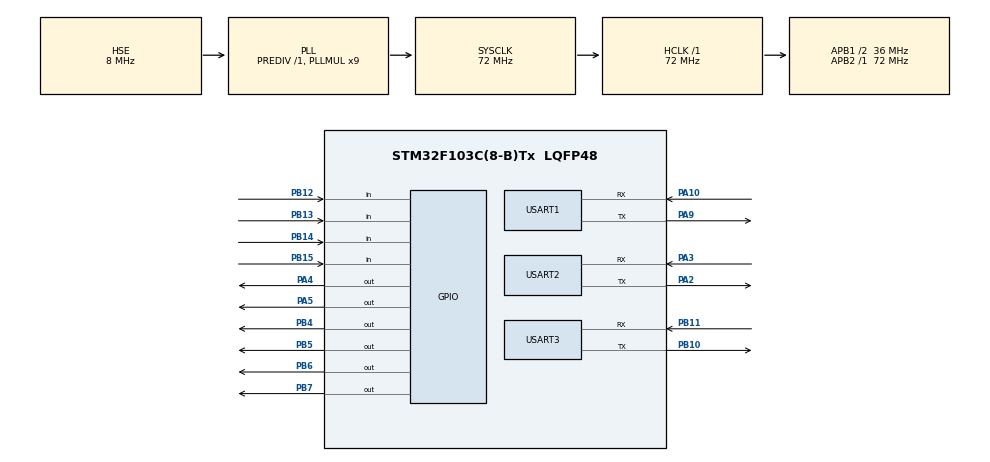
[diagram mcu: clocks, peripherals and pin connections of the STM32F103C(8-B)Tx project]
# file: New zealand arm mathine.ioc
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FREERTOS.INCLUDE_eTaskGetState=1
FREERTOS.Queues01=serialRecQueue,16,uint16_t,0,Dynamic,NULL,NULL;serialSendQueue,16,uint16_t,0,Dynamic,NULL,NULL
FREERTOS.Tasks01=defaultTask,0,128,StartDefaultTask,Default,NULL,Dynamic,NULL,NULL;ledTask,-2,128,LedTask,Default,NULL,Dynamic,NULL,NULL
FREERTOS.configGENERATE_RUN_TIME_STATS=1
Mcu.Family=STM32F1
Mcu.Name=STM32F103C(8-B)Tx
Mcu.Package=LQFP48
NVIC.PriorityGroup=NVIC_PRIORITYGROUP_4
NVIC.TIM1_UP_IRQn=true\:0\:0\:false\:false\:true\:false\:false\:true
NVIC.TimeBase=TIM1_UP_IRQn
NVIC.TimeBaseIP=TIM1
NVIC.USART1_IRQn=true\:5\:0\:false\:false\:true\:true\:true\:true
NVIC.USART2_IRQn=true\:5\:0\:false\:false\:true\:true\:true\:true
NVIC.USART3_IRQn=true\:5\:0\:false\:false\:true\:true\:true\:true
PA10.Mode=Asynchronous
PA10.Signal=USART1_RX
PA13.Mode=Serial_Wire
PA13.Signal=SYS_JTMS-SWDIO
PA14.Mode=Serial_Wire
PA14.Signal=SYS_JTCK-SWCLK
PA2.Mode=Asynchronous
PA2.Signal=USART2_TX
PA3.Mode=Asynchronous
PA3.Signal=USART2_RX
PA4.Signal=GPIO_Output
PA5.Signal=GPIO_Output
PA9.Mode=Asynchronous
PA9.Signal=USART1_TX
PB10.Mode=Asynchronous
PB10.Signal=USART3_TX
PB11.Mode=Asynchronous
PB11.Signal=USART3_RX
PB12.Signal=GPIO_Input
PB13.Signal=GPIO_Input
PB14.Signal=GPIO_Input
PB15.Signal=GPIO_Input
PB4.Signal=GPIO_Output
PB5.Signal=GPIO_Output
PB6.Signal=GPIO_Output
PB7.Signal=GPIO_Output
PC14-OSC32_IN.Mode=LSE-External-Oscillator
PC14-OSC32_IN.Signal=RCC_OSC32_IN
PC15-OSC32_OUT.Mode=LSE-External-Oscillator
PC15-OSC32_OUT.Signal=RCC_OSC32_OUT
PD0-OSC_IN.Mode=HSE-External-Oscillator
PD0-OSC_IN.Signal=RCC_OSC_IN
PD1-OSC_OUT.Mode=HSE-External-Oscillator
PD1-OSC_OUT.Signal=RCC_OSC_OUT
ProjectManager.HeapSize=0x200
ProjectManager.StackSize=0x400
ProjectManager.TargetToolchain=MDK-ARM V5
RCC.AHBFreq_Value=72000000
RCC.APB1CLKDivider=RCC_HCLK_DIV2
RCC.APB1Freq_Value=36000000
RCC.APB1TimFreq_Value=72000000
RCC.APB2Freq_Value=72000000
RCC.APB2TimFreq_Value=72000000
RCC.HCLKFreq_Value=72000000
RCC.PLLMUL=RCC_PLL_MUL9
RCC.PLLSourceVirtual=RCC_PLLSOURCE_HSE
RCC.SYSCLKFreq_VALUE=72000000
RCC.SYSCLKSource=RCC_SYSCLKSOURCE_PLLCLK
RCC.USBFreq_Value=72000000
USART1.VirtualMode=VM_ASYNC
USART2.VirtualMode=VM_ASYNC
USART3.VirtualMode=VM_ASYNC
VP_FREERTOS_VS_CMSIS_V1.Mode=CMSIS_V1
VP_IWDG_VS_IWDG.Mode=IWDG_Activate
VP_SYS_VS_tim1.Mode=TIM1
board=custom

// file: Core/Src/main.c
/* USER CODE BEGIN Header */
/**
  ******************************************************************************
  * @file           : main.c
  * @brief          : Main program body
  ******************************************************************************
  * @attention
  *
  * <h2><center>&copy; Copyright (c) 2019 STMicroelectronics.
  * All rights reserved.</center></h2>
  *
  * This software component is licensed by ST under Ultimate Liberty license
  * SLA0044, the "License"; You may not use this file except in compliance with
  * the License. You may obtain a copy of the License at:
  *                             www.st.com/SLA0044
  *
  ******************************************************************************
  */
/* USER CODE END Header */

#include "main.h"
#include "cmsis_os.h"
#include "iwdg.h"
#include "usart.h"
#include "gpio.h"

void SystemClock_Config(void);
void MX_FREERTOS_Init(void);

int main(void)
{

  /* MCU Configuration--------------------------------------------------------*/

  /* Reset of all peripherals, Initializes the Flash interface and the Systick. */
  HAL_Init();

  /* Configure the system clock */
  SystemClock_Config();

  /* Initialize all configured peripherals */
  MX_GPIO_Init();
  MX_IWDG_Init();
  MX_USART1_UART_Init();
  MX_USART2_UART_Init();
  MX_USART3_UART_Init();

  /* Call init function for freertos objects (in freertos.c) */
  MX_FREERTOS_Init();

  /* Start scheduler */
  osKernelStart();
//	vTaskStartScheduler();

  /* We should never get here as control is now taken by the scheduler */

  /* Infinite loop */
  while (1)
  {

  }
}

void SystemClock_Config(void)
{
  RCC_OscInitTypeDef RCC_OscInitStruct = {0};
  RCC_ClkInitTypeDef RCC_ClkInitStruct = {0};

  /** Initializes the CPU, AHB and APB busses clocks
  */
  RCC_OscInitStruct.OscillatorType = RCC_OSCILLATORTYPE_LSI|RCC_OSCILLATORTYPE_HSE;
  RCC_OscInitStruct.HSEState = RCC_HSE_ON;
  RCC_OscInitStruct.HSEPredivValue = RCC_HSE_PREDIV_DIV1;
  RCC_OscInitStruct.HSIState = RCC_HSI_ON;
  RCC_OscInitStruct.LSIState = RCC_LSI_ON;
  RCC_OscInitStruct.PLL.PLLState = RCC_PLL_ON;
  RCC_OscInitStruct.PLL.PLLSource = RCC_PLLSOURCE_HSE;
  RCC_OscInitStruct.PLL.PLLMUL = RCC_PLL_MUL9;
  if (HAL_RCC_OscConfig(&RCC_OscInitStruct) != HAL_OK)
  {
    Error_Handler();
  }
  /** Initializes the CPU, AHB and APB busses clocks
  */
  RCC_ClkInitStruct.ClockType = RCC_CLOCKTYPE_HCLK|RCC_CLOCKTYPE_SYSCLK
                              |RCC_CLOCKTYPE_PCLK1|RCC_CLOCKTYPE_PCLK2;
  RCC_ClkInitStruct.SYSCLKSource = RCC_SYSCLKSOURCE_PLLCLK;
  RCC_ClkInitStruct.AHBCLKDivider = RCC_SYSCLK_DIV1;
  RCC_ClkInitStruct.APB1CLKDivider = RCC_HCLK_DIV2;
  RCC_ClkInitStruct.APB2CLKDivider = RCC_HCLK_DIV1;

  if (HAL_RCC_ClockConfig(&RCC_ClkInitStruct, FLASH_LATENCY_2) != HAL_OK)
  {
    Error_Handler();
  }
}

void HAL_TIM_PeriodElapsedCallback(TIM_HandleTypeDef *htim)
{
  if (htim->Instance == TIM1) {
    HAL_IncTick();
  }
}

void Error_Handler(void)
{
}

/************************ (C) COPYRIGHT STMicroelectronics *****END OF FILE****/

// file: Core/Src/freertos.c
/* USER CODE BEGIN Header */
/**
  ******************************************************************************
  * File Name          : freertos.c
  * Description        : Code for freertos applications
  ******************************************************************************
  * @attention
  *
  * <h2><center>&copy; Copyright (c) 2019 STMicroelectronics.
  * All rights reserved.</center></h2>
  *
  * This software component is licensed by ST under Ultimate Liberty license
  * SLA0044, the "License"; You may not use this file except in compliance with
  * the License. You may obtain a copy of the License at:
  *                             www.st.com/SLA0044
  *
  ******************************************************************************
  */
/* USER CODE END Header */

#include "FreeRTOS.h"
#include "task.h"
#include "main.h"
#include "cmsis_os.h"
#include "stepper_app.h"
#include "iwdg.h"
#include "serial_queue_app.h"

osThreadId defaultTaskHandle;
osThreadId ledTaskHandle;
//osMessageQId serialRecQueueHandle;
//osMessageQId serialSendQueueHandle;

void StartDefaultTask(void const * argument);
void LedTask(void const * argument);

void MX_FREERTOS_Init(void); /* (MISRA C 2004 rule 8.1) */

/* Hook prototypes */
void configureTimerForRunTimeStats(void);
unsigned long getRunTimeCounterValue(void);

/* USER CODE BEGIN 1 */
/* Functions needed when configGENERATE_RUN_TIME_STATS is on */
__weak void configureTimerForRunTimeStats(void)
{

}

__weak unsigned long getRunTimeCounterValue(void)
{
return 0;
}
/* USER CODE END 1 */

void MX_FREERTOS_Init(void) {

  /* Create the queue(s) */
  /* definition and creation of serialRecQueue */
//  osMessageQDef(serialRecQueue, 16, uint16_t);
//  serialRecQueueHandle = osMessageCreate(osMessageQ(serialRecQueue), NULL);

  /* definition and creation of serialSendQueue */
//  osMessageQDef(serialSendQueue, 16, uint16_t);
//  serialSendQueueHandle = osMessageCreate(osMessageQ(serialSendQueue), NULL);

  /* Create the thread(s) */
  /* definition and creation of defaultTask */
  osThreadDef(defaultTask, StartDefaultTask, osPriorityNormal, 0, 128);
  defaultTaskHandle = osThreadCreate(osThread(defaultTask), NULL);

  /* definition and creation of ledTask */
  osThreadDef(ledTask, LedTask, osPriorityLow, 0, 128);
  ledTaskHandle = osThreadCreate(osThread(ledTask), NULL);

  /* USER CODE BEGIN RTOS_THREADS */
  /* add threads, ... */

//	printf("---------------------------------------\r\n");
//	printf("Init --> MX_FREERTOS_Init()\r\n");
	StepperInit();
	data_queue_task_init();
  /* USER CODE END RTOS_THREADS */

}

void StartDefaultTask(void const * argument)
{

  /* USER CODE BEGIN StartDefaultTask */
  /* Infinite loop */
  for(;;)
  {
		HAL_IWDG_Refresh(&hiwdg);
		osDelay(10);
  }
  /* USER CODE END StartDefaultTask */
}

void LedTask(void const * argument)
{
  /* USER CODE BEGIN LedTask */
  /* Infinite loop */
  for(;;)
  {
//		printf("Task --> LedTask()\r\n");
		HAL_GPIO_TogglePin(GPIOA, GPIO_PIN_5);
//		HAL_GPIO_TogglePin(GPIOB, GPIO_PIN_4);
//		HAL_GPIO_TogglePin(GPIOB, GPIO_PIN_5);
//		HAL_GPIO_TogglePin(GPIOB, GPIO_PIN_6);
//		HAL_GPIO_TogglePin(GPIOB, GPIO_PIN_7);
		osDelay(1000);
  }
  /* USER CODE END LedTask */
}

/************************ (C) COPYRIGHT STMicroelectronics *****END OF FILE****/
